# STM32F412Cx register map
File version: 1.0
Registers are 32-bit, read-write, reset 0x0 unless marked. A register's access mark holds for its fields unless they carry their own. Offsets are from the block's base; [hi:lo] are bit positions; {n}, {i} and the like mark numbered series.

## GPIOA — General Purpose I/O
Base 0x40020000
Same registers: GPIOB 0x40020400, GPIOC 0x40020800, GPIOH 0x40021C00
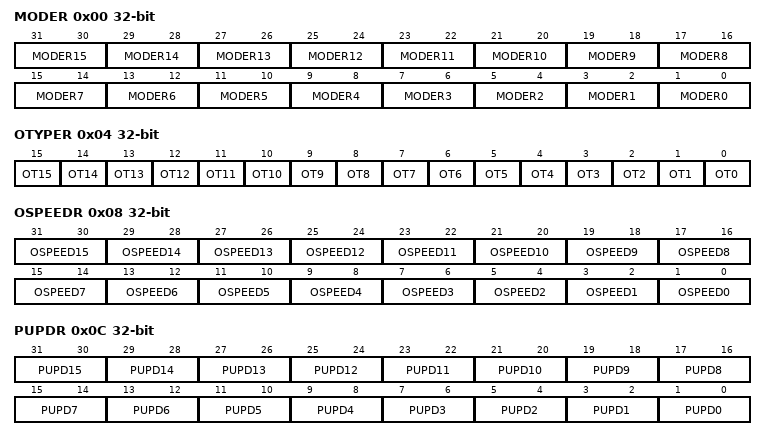
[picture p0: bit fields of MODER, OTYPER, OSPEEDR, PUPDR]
0x00 MODER — GPIO port mode register
  [2n+1:2n] MODER{n} (n=0..15)
0x04 OTYPER — GPIO port output type register
  [n] OT{n} (n=0..15)
0x08 OSPEEDR — GPIO port output speed register
  [2n+1:2n] OSPEED{n} (n=0..15)
0x0C PUPDR — GPIO port pull-up/pull-down register
  [2n+1:2n] PUPD{n} (n=0..15)
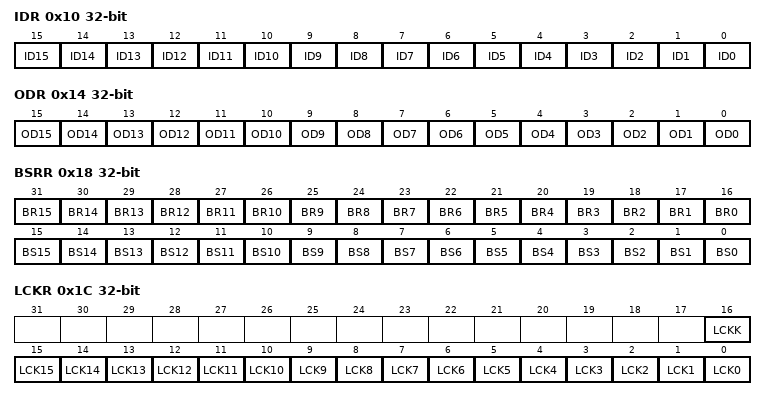
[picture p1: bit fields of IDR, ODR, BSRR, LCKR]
0x10 IDR — GPIO port input data register
  [n] ID{n} (n=0..15)
0x14 ODR — GPIO port output data register
  [n] OD{n} (n=0..15)
0x18 BSRR — GPIO port bit set/reset register
  [n+16] BR{n} (n=0..15), [n] BS{n} (n=0..15)
0x1C LCKR — GPIO port configuration lock register
  [16] LCKK, [n] LCK{n} (n=0..15)
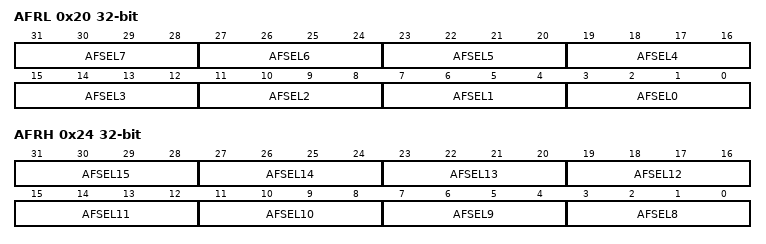
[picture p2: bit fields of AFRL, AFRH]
0x20 AFRL — GPIO alternate function registers
  [4n+3:4n] AFSEL{n} (n=0..7)
0x24 AFRH — GPIO alternate function registers
  [4n-29:4n-32] AFSEL{n} (n=8..15)

## CRC — CRC calculation unit
Base 0x40023000
0x00 DR — CRC Data register
  [31:0] DR — Data register bits
0x04 IDR 8-bit — CRC Independent data register
  [7:0] IDR — General-purpose 8-bit data register bits
0x08 CR — CRC Control register
  [0] RESET — RESET bit

## FLASH — FLASH Registers
Base 0x40023C00
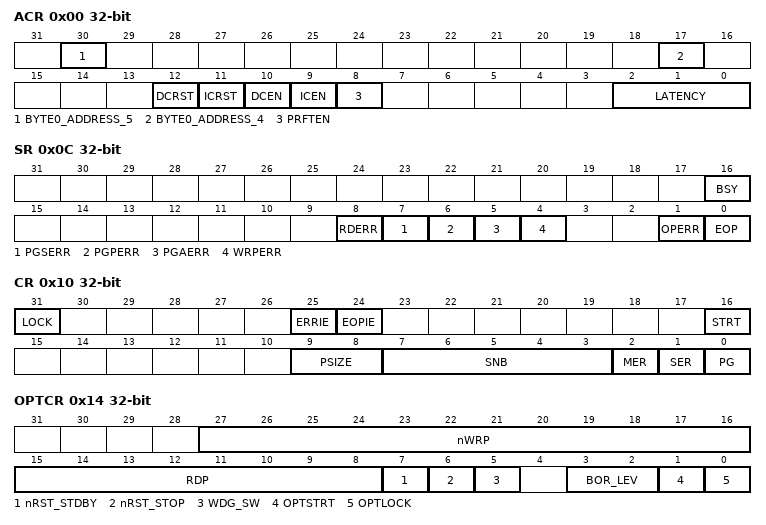
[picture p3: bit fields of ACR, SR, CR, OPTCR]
0x00 ACR — FLASH access control register
  [30] BYTE0_ADDRESS_5
  [17] BYTE0_ADDRESS_4
  [12] DCRST
  [11] ICRST
  [10] DCEN
  [9] ICEN
  [8] PRFTEN
  [2:0] LATENCY
    0=FLASH Zero wait state; 1=FLASH One wait state; 2=FLASH Two wait states; 3=FLASH Three wait states; 4=FLASH Four wait states; 5=FLASH five wait state; 6=FLASH six wait state; 7=FLASH seven wait states
0x04 KEYR — FLASH key register
0x08 OPTKEYR — FLASH option key register
0x0C SR — FLASH status register
  [16] BSY, [8] RDERR, [7] PGSERR, [6] PGPERR, [5] PGAERR, [4] WRPERR, [1] OPERR, [0] EOP
0x10 CR — FLASH control register
  [31] LOCK, [25] ERRIE, [24] EOPIE, [16] STRT, [9:8] PSIZE, [7:3] SNB, [2] MER, [1] SER, [0] PG
0x14 OPTCR — FLASH option control register
  [27:16] nWRP, [15:8] RDP, [7] nRST_STDBY, [6] nRST_STOP, [5] WDG_SW, [3:2] BOR_LEV, [1] OPTSTRT, [0] OPTLOCK
0x18 OPTCR1 — FLASH option control register 1
  [27:16] nWRP

## DMA1
Base 0x40026000
Same registers: DMA2 0x40026400
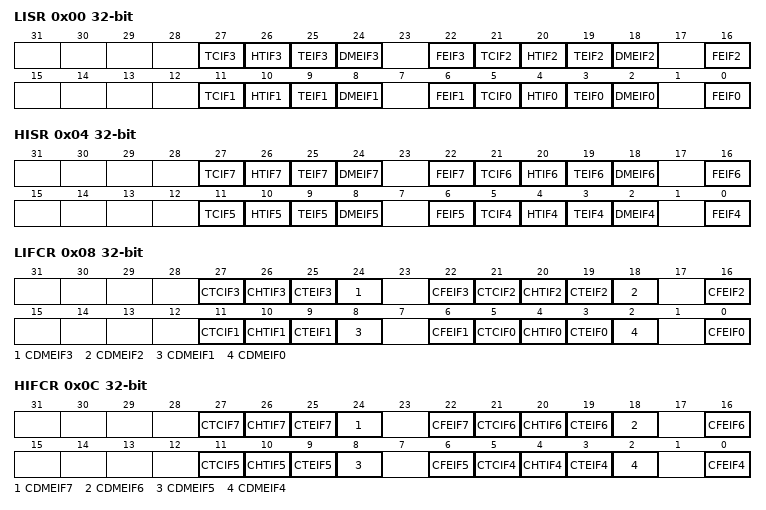
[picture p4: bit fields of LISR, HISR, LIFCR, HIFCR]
0x00 LISR — DMA low interrupt status register
  [27] TCIF3, [26] HTIF3, [25] TEIF3, [24] DMEIF3, [22] FEIF3, [21] TCIF2, [20] HTIF2, [19] TEIF2, [18] DMEIF2, [16] FEIF2, [11] TCIF1, [10] HTIF1, [9] TEIF1, [8] DMEIF1, [6] FEIF1, [5] TCIF0, [4] HTIF0, [3] TEIF0, [2] DMEIF0, [0] FEIF0
0x04 HISR — DMA high interrupt status register
  [27] TCIF7, [26] HTIF7, [25] TEIF7, [24] DMEIF7, [22] FEIF7, [21] TCIF6, [20] HTIF6, [19] TEIF6, [18] DMEIF6, [16] FEIF6, [11] TCIF5, [10] HTIF5, [9] TEIF5, [8] DMEIF5, [6] FEIF5, [5] TCIF4, [4] HTIF4, [3] TEIF4, [2] DMEIF4, [0] FEIF4
0x08 LIFCR — DMA low interrupt flag clear register
  [27] CTCIF3, [26] CHTIF3, [25] CTEIF3, [24] CDMEIF3, [22] CFEIF3, [21] CTCIF2, [20] CHTIF2, [19] CTEIF2, [18] CDMEIF2, [16] CFEIF2, [11] CTCIF1, [10] CHTIF1, [9] CTEIF1, [8] CDMEIF1, [6] CFEIF1, [5] CTCIF0, [4] CHTIF0, [3] CTEIF0, [2] CDMEIF0, [0] CFEIF0
0x0C HIFCR — DMA high interrupt flag clear register
  [27] CTCIF7, [26] CHTIF7, [25] CTEIF7, [24] CDMEIF7, [22] CFEIF7, [21] CTCIF6, [20] CHTIF6, [19] CTEIF6, [18] CDMEIF6, [16] CFEIF6, [11] CTCIF5, [10] CHTIF5, [9] CTEIF5, [8] CDMEIF5, [6] CFEIF5, [5] CTCIF4, [4] CHTIF4, [3] CTEIF4, [2] CDMEIF4, [0] CFEIF4
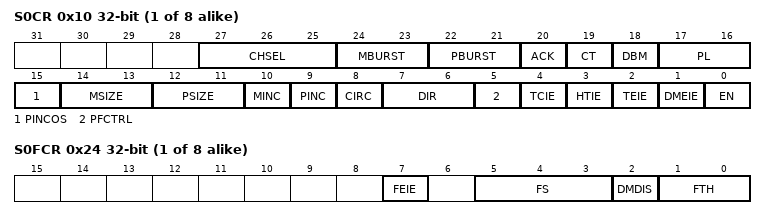
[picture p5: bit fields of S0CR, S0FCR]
{0x10+0x18*i} S{i}CR (i=0..7) — DMA stream x configuration register
  [27:25] CHSEL, [24:23] MBURST, [22:21] PBURST, [20] ACK, [19] CT, [18] DBM, [17:16] PL, [15] PINCOS, [14:13] MSIZE, [12:11] PSIZE, [10] MINC, [9] PINC, [8] CIRC, [7:6] DIR, [5] PFCTRL, [4] TCIE, [3] HTIE, [2] TEIE, [1] DMEIE, [0] EN
{0x14+0x18*i} S{i}NDTR (i=0..7) — DMA stream x number of data register
  [15:0] SxNDT
{0x18+0x18*i} S{i}PAR (i=0..7) — DMA stream x peripheral address register
  [31:0] PA — Peripheral Address
{0x1C+0x18*i} S{i}M0AR (i=0..7) — DMA stream x memory 0 address register
  [31:0] M0A — Memory Address
{0x20+0x18*i} S{i}M1AR (i=0..7) — DMA stream x memory 1 address register
  [31:0] M1A — Memory Address
{0x24+0x18*i} S{i}FCR (i=0..7) — DMA stream x FIFO control register
  [7] FEIE, [5:3] FS, [2] DMDIS, [1:0] FTH

## RNG
Base 0x50060800
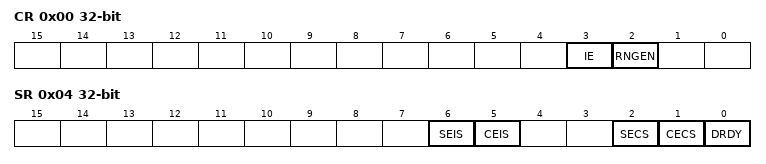
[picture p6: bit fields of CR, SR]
0x00 CR — RNG control register
  [3] IE, [2] RNGEN
0x04 SR — RNG status register
  [6] SEIS, [5] CEIS, [2] SECS, [1] CECS, [0] DRDY
0x08 DR — RNG data register

## DBGMCU — Debug MCU
Base 0xE0042000
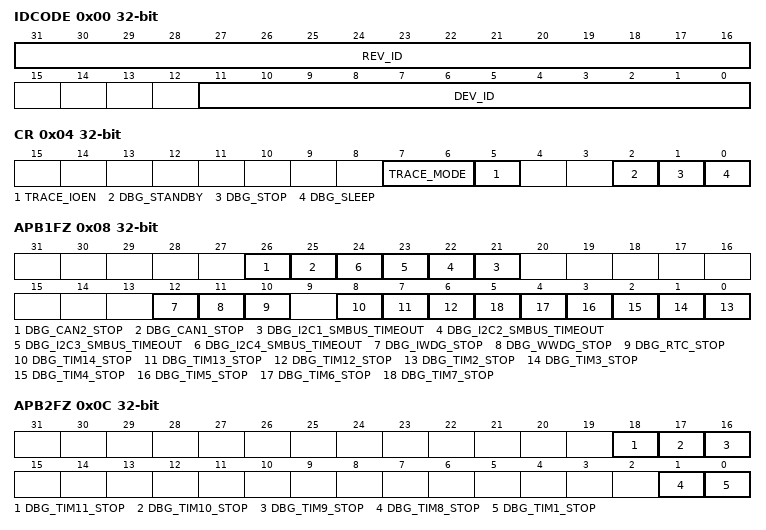
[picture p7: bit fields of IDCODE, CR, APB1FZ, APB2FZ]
0x00 IDCODE — MCU device ID code
  [31:16] REV_ID, [11:0] DEV_ID
0x04 CR — Debug MCU configuration register
  [7:6] TRACE_MODE, [5] TRACE_IOEN, [2] DBG_STANDBY, [1] DBG_STOP, [0] DBG_SLEEP
0x08 APB1FZ — Debug MCU APB1 freeze register
  [26] DBG_CAN2_STOP, [25] DBG_CAN1_STOP, [n+20] DBG_I2C{n}_SMBUS_TIMEOUT (n=1..4), [12] DBG_IWDG_STOP, [11] DBG_WWDG_STOP, [10] DBG_RTC_STOP, [8] DBG_TIM14_STOP, [7] DBG_TIM13_STOP, [6] DBG_TIM12_STOP, [n-2] DBG_TIM{n}_STOP (n=2..7)
0x0C APB2FZ — Debug MCU APB2 freeze register
  [18] DBG_TIM11_STOP, [17] DBG_TIM10_STOP, [16] DBG_TIM9_STOP, [1] DBG_TIM8_STOP, [0] DBG_TIM1_STOP
